# STM32F412Cx register map
File version: 1.0
Registers are 32-bit, read-write, reset 0x0 unless marked. A register's access mark holds for its fields unless they carry their own. Offsets are from the block's base; [hi:lo] are bit positions; lines under a group give offsets from that group; {n}, {i} and the like mark numbered series.

## ADC1 — Analog to Digital Converter
Base 0x40012000
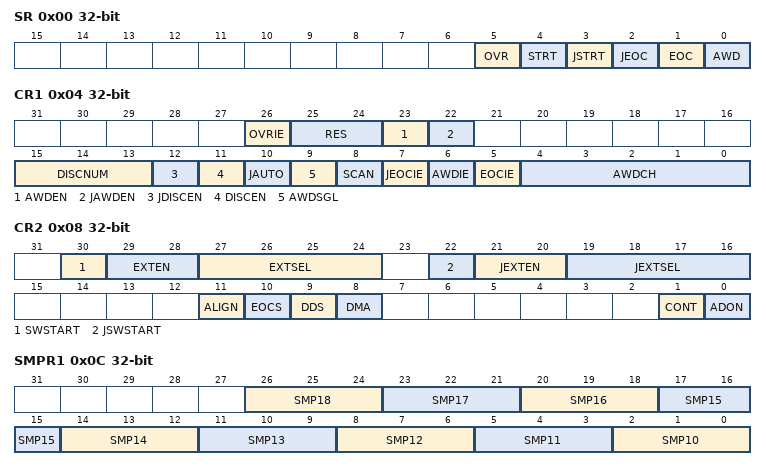
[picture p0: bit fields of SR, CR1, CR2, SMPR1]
0x00 SR — ADC status register
  [5] OVR — Overrun flag
  [4] STRT — Regular channel Start flag
  [3] JSTRT — Injected channel Start flag
  [2] JEOC — Injected channel end of conversion
  [1] EOC — End of conversion
  [0] AWD — Analog watchdog flag
0x04 CR1 — ADC control register 1
  [26] OVRIE — overrun interrupt enable
  [25:24] RES — RES[2:0] bits (Resolution)
    0=RESOLUTION_12B (ADC resolution 12 bits); 1=RESOLUTION_10B (ADC resolution 10 bits); 2=RESOLUTION_8B (ADC resolution 8 bits); 3=RESOLUTION_6B (ADC resolution 6 bits)
  [23] AWDEN — Analog watchdog enable on regular channels
  [22] JAWDEN — Analog watchdog enable on injected channels
  [15:13] DISCNUM — DISCNUM[2:0] bits (Discontinuous mode channel count)
  [12] JDISCEN — Discontinuous mode on injected channels
    0=DISABLE (ADC group injected sequencer discontinuous mode disable); 1=DISCONT_1RANK (ADC group injected sequencer discontinuous mode enable with sequence interruption every rank)
  [11] DISCEN — Discontinuous mode on regular channels
  [10] JAUTO — Automatic injected group conversion
    0=INDEPENDENT (ADC group injected conversion trigger independent. Setting mandatory if ADC group injected injected trigger source is set to an external trigger.); 1=FROM_GRP_REGULAR (ADC group injected conversion trigger from ADC group regular. Setting compliant only with group injected trigger source set to SW start, without any further action on ADC group injected conversion start or stop: in this case, ADC group injected is controlled only from ADC group regular.)
  [9] AWDSGL — Enable the watchdog on a single channel in scan mode
  [8] SCAN — Scan mode
    0=DISABLE (ADC conversion is performed in unitary conversion mode (one channel converted, that defined in rank 1). Configuration of both groups regular and injected sequencers (sequence length, ...) is discarded: equivalent to length of 1 rank.); 1=ENABLE (ADC conversions are performed in sequence conversions mode, according to configuration of both groups regular and injected sequencers (sequence length, ...).)
  [7] JEOCIE — Interrupt enable for injected channels
  [6] AWDIE — AAnalog Watchdog interrupt enable
  [5] EOCIE — Interrupt enable for EOC
  [4:0] AWDCH — AWDCH[4:0] bits (Analog watchdog channel select bits)
0x08 CR2 — ADC control register 2
  [30] SWSTART — Start Conversion of regular channels
  [29:28] EXTEN — EXTEN[1:0] bits (External Trigger Conversion mode for regular channelsp)
    1=RISING (ADC group regular conversion trigger polarity set to rising edge); 2=FALLING (ADC group regular conversion trigger polarity set to falling edge); 3=RISINGFALLING (ADC group regular conversion trigger polarity set to both rising and falling edges)
  [27:24] EXTSEL — EXTSEL[3:0] bits (External Event Select for regular group)
  [22] JSWSTART — Start Conversion of injected channels
  [21:20] JEXTEN — JEXTEN[1:0] bits (External Trigger Conversion mode for injected channelsp)
    1=RISING (ADC group injected conversion trigger polarity set to rising edge); 2=FALLING (ADC group injected conversion trigger polarity set to falling edge); 3=RISINGFALLING (ADC group injected conversion trigger polarity set to both rising and falling edges)
  [19:16] JEXTSEL — JEXTSEL[3:0] bits (External event select for injected group)
  [11] ALIGN — Data Alignment
    0=RIGHT (ADC conversion data alignment: right aligned (alignment on data register LSB bit 0)); 1=LEFT (ADC conversion data alignment: left aligned (alignment on data register MSB bit 15))
  [10] EOCS — End of conversion selection
    0=SEQUENCE_CONV (ADC flag EOC (end of unitary conversion) selected); 1=UNITARY_CONV (ADC flag EOS (end of sequence conversions) selected)
  [9] DDS — DMA disable selection (Single ADC)
  [8] DMA — Direct Memory access mode
  [1] CONT — Continuous Conversion
    0=SINGLE (ADC conversions are performed in single mode: one conversion per trigger); 1=CONTINUOUS (ADC conversions are performed in continuous mode: after the first trigger, following conversions launched successively automatically)
  [0] ADON — A/D Converter ON / OFF
0x0C SMPR1 — ADC sample time register 1
  [3n-28:3n-30] SMP{n} (n=10..18) — SMP{n}[2:0] bits (Channel {n} Sample time selection)
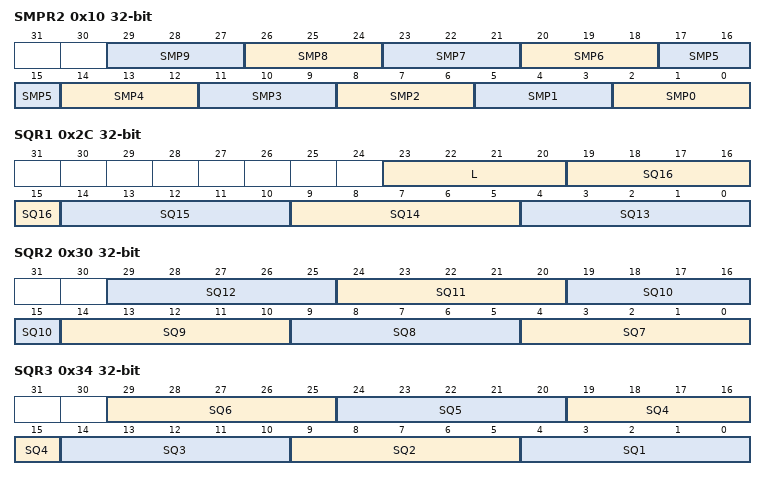
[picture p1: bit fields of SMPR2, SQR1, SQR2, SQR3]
0x10 SMPR2 — ADC sample time register 2
  [3n+2:3n] SMP{n} (n=0..9) — SMP{n}[2:0] bits (Channel {n} Sample time selection)
{0x10+4i} JOFR{i} (i=1..4) — ADC injected channel data
  [11:0] JOFFSET{i} — Data offset for injected channel {i}
0x24 HTR — ADC watchdog higher threshold register
  [11:0] HT — Analog watchdog high threshold
0x28 LTR — ADC watchdog lower threshold register
  [11:0] LT — Analog watchdog low threshold
0x2C SQR1 — ADC regular sequence register 1
  [23:20] L — L[3:0] bits (Regular channel sequence length)
    0=DISABLE (ADC group regular sequencer disable (equivalent to sequencer of 1 rank: ADC conversion on only 1 channel)); {v}=ENABLE_{v+1}RANKS (ADC group regular sequencer enable with {v+1} ranks in the sequence) (v=1..15)
  [5n-61:5n-65] SQ{n} (n=13..16) — SQ{n}[4:0] bits ({n}th conversion in regular sequence)
0x30 SQR2 — ADC regular sequence register 2
  [5n-31:5n-35] SQ{n} (n=7..12) — SQ{n}[4:0] bits ({n}th conversion in regular sequence)
0x34 SQR3 — ADC regular sequence register 3
  [29:25] SQ6 — SQ6[4:0] bits (6th conversion in regular sequence)
  [24:20] SQ5 — SQ5[4:0] bits (5th conversion in regular sequence)
  [19:15] SQ4 — SQ4[4:0] bits (4th conversion in regular sequence)
  [14:10] SQ3 — SQ3[4:0] bits (3rd conversion in regular sequence)
  [9:5] SQ2 — SQ2[4:0] bits (2nd conversion in regular sequence)
  [4:0] SQ1 — SQ1[4:0] bits (1st conversion in regular sequence)
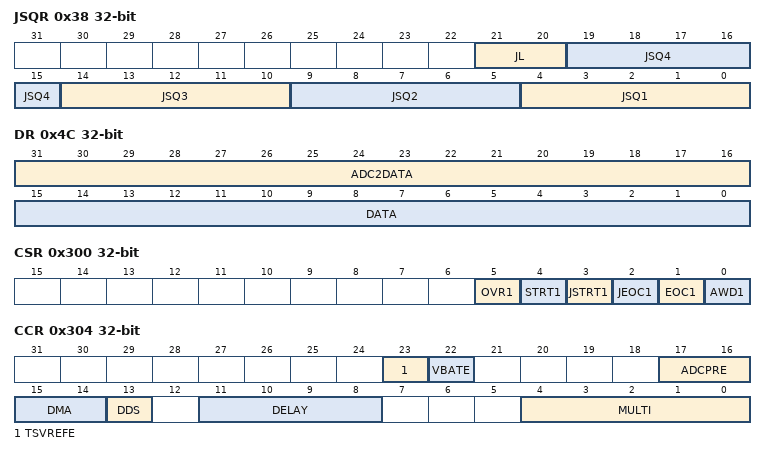
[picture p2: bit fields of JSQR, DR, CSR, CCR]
0x38 JSQR — ADC injected sequence register
  [21:20] JL — JL[1:0] bits (Injected Sequence length)
    0=DISABLE (ADC group injected sequencer disable (equivalent to sequencer of 1 rank: ADC conversion on only 1 channel)); 1=ENABLE_2RANKS (ADC group injected sequencer enable with 2 ranks in the sequence); 2=ENABLE_3RANKS (ADC group injected sequencer enable with 3 ranks in the sequence); 3=ENABLE_4RANKS (ADC group injected sequencer enable with 4 ranks in the sequence)
  [19:15] JSQ4 — JSQ4[4:0] bits (4th conversion in injected sequence)
  [14:10] JSQ3 — JSQ3[4:0] bits (3rd conversion in injected sequence)
  [9:5] JSQ2 — JSQ2[4:0] bits (2nd conversion in injected sequence)
  [4:0] JSQ1 — JSQ1[4:0] bits (1st conversion in injected sequence)
{0x38+4i} JDR{i} (i=1..4) — ADC injected data register {i}
  [15:0] JDATA — Injected data
0x4C DR — ADC regular data register
  [31:16] ADC2DATA
  [15:0] DATA — Regular data
0x300 CSR — ADC Common status register
  [5] OVR1 — ADC1 DMA overrun flag
  [4] STRT1 — ADC1 Regular channel Start flag
  [3] JSTRT1 — ADC1 Injected channel Start flag
  [2] JEOC1 — ADC1 Injected channel end of conversion
  [1] EOC1 — ADC1 End of conversion
  [0] AWD1 — ADC1 Analog watchdog flag
0x304 CCR — ADC common control register
  [23] TSVREFE — Temperature Sensor and VREFINT Enable
  [22] VBATE — VBAT Enable
  [17:16] ADCPRE — ADCPRE[1:0] bits (ADC prescaler)
    0=DIV2 (ADC synchronous clock derived from AHB clock with prescaler division by 2); 1=DIV4 (ADC synchronous clock derived from AHB clock with prescaler division by 4); 2=DIV6 (ADC synchronous clock derived from AHB clock with prescaler division by 6); 3=DIV8 (ADC synchronous clock derived from AHB clock with prescaler division by 8)
  [15:14] DMA — DMA[1:0] bits (Direct Memory Access mode for multimode)
  [13] DDS — DMA disable selection (Multi-ADC mode)
  [11:8] DELAY — DELAY[3:0] bits (Delay between 2 sampling phases)
  [4:0] MULTI — MULTI[4:0] bits (Multi-ADC mode selection)
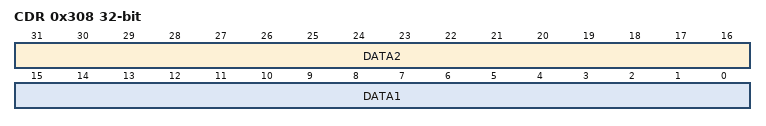
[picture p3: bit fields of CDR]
0x308 CDR — ADC common regular data register for dual AND triple modes
  [31:16] DATA2 — 2nd data of a pair of regular conversions
  [15:0] DATA1 — 1st data of a pair of regular conversions
